AUTOSAR XML (schema 4-0-3)
standard types defined: Boolean, UInt16, UInt8
package /AUTOSAR_Platform/DataConstrs
  range DC_Boolean: raw 0..1
  range DC_UInt16: raw 0..65535
  range DC_UInt8: raw 0..255
package /PATAC/MSM/ComponentTypes
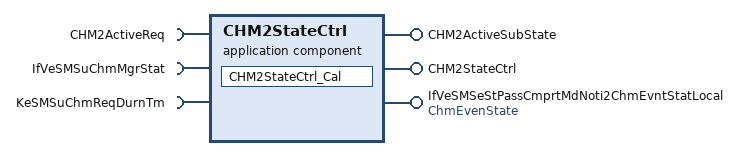
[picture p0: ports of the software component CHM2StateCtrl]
  application sw component type CHM2StateCtrl
    provide port CHM2ActiveSubState: nonqueued-sender-com-spec{data-element=CHM2ActiveSubState/Val, init-value=0}, provided-interface=CHM2ActiveSubState
    provide port CHM2StateCtrl: server-com-spec{operation=Cal, queue-length=1}, provided-interface=CHM2StateCtrl
    provide port IfVeSMSeStPassCmprtMdNoti2ChmEvntStatLocal: nonqueued-sender-com-spec{data-element=ChmEvenState/Val, init-value=0}, provided-interface=ChmEvenState
    require port CHM2ActiveReq: nonqueued-receiver-com-spec{data-element=CHM2ActiveReq/Val, filter=data-filter-type=ALWAYS, init-value=0}, required-interface=CHM2ActiveReq
    require port IfVeSMSuChmMgrStat: nonqueued-receiver-com-spec{data-element=IfVeSMSuChmMgrStat/Val, filter=data-filter-type=ALWAYS, init-value=0}, required-interface=IfVeSMSuChmMgrStat
    require port KeSMSuChmReqDurnTm: parameter-require-com-spec{init-value=200, parameter=Val}, required-interface=KeSMSuChmReqDurnTm
    behavior CHM2StateCtrl_InternalBehavior
      operation invoked event OIT_CHM2StateCtrl_Cal_CHM2StateCtrl_Cal: start-on-event=CHM2StateCtrl_Cal, operation=CHM2StateCtrl.Cal
      runnable CHM2StateCtrl_Cal
        data-receive-point-by-arguments:
          access REC_CHM2ActiveReq_Val: accessed-variable=CHM2ActiveReq.Val
          access REC_IfVeSMSuChmMgrStat_Val: accessed-variable=IfVeSMSuChmMgrStat.Val
        data-send-points:
          access SEND_CHM2ActiveSubState_Val: accessed-variable=CHM2ActiveSubState.Val
          access SEND_IfVeSMSeStPassCmprtMdNoti2ChmEvntStatLocal_Val: accessed-variable=IfVeSMSeStPassCmprtMdNoti2ChmEvntStatLocal.Val
        parameter access PA_KeSMSuChmReqDurnTm_Val: accessed-parameter=KeSMSuChmReqDurnTm.Val
  swc implementation CHM2StateCtrl_Implementation: behavior=CHM2StateCtrl_InternalBehavior
    code-descriptors:
      code Default: artifact-descriptors=autosar-engineering-object={short-label=Default, category=SWSRC}
package /PATAC/MSM/ModeAdjust/DataType
  impl type EventSts1: category=VALUE, base-type=UInt8, sw-calibration-access=READ-ONLY, compu {0=EventSts_NoAct, 1=EventSts_Act, 2=EventSts_CancleChime}, type-emitter=RTE
package /PATAC/MSM/ModeAdjust/PortInterface
  client server interface CHM2StateCtrl
    operation Cal
  4 x sender receiver interface:
    CHM2ActiveReq: invalidation-policy{data-element=CHM2ActiveReq/Val, handle-invalid=DONT-INVALIDATE}
      data Val: type=Boolean
    CHM2ActiveSubState: invalidation-policy{data-element=CHM2ActiveSubState/Val, handle-invalid=DONT-INVALIDATE}
      data Val: type=Boolean
    ChmEvenState: invalidation-policy{data-element=ChmEvenState/Val, handle-invalid=DONT-INVALIDATE}
      data Val: type=EventSts1
    IfVeSMSuChmMgrStat: invalidation-policy{data-element=IfVeSMSuChmMgrStat/Val, handle-invalid=DONT-INVALIDATE}
      data Val: type=UInt16
package /PATAC/MSM/PortInterfaces
  parameter interface KeSMSuChmReqDurnTm
    parameter data prototype Val: sw-calibration-access=READ-WRITE, type=UInt8
